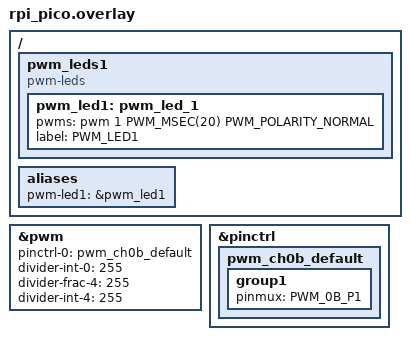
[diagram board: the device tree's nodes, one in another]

#include </home/tatiana/zephyrproject/zephyr/include/zephyr/dt-bindings/pinctrl/rpi-pico-rp2040-pinctrl.h>

/ {
	pwm_leds1 {
		compatible = "pwm-leds";
		pwm_led1: pwm_led_1 {
			status = "okay";
			pwms = <&pwm 1 PWM_MSEC(20) PWM_POLARITY_NORMAL>;
			label = "PWM_LED1";
		};
	};

	aliases {
		pwm-led1 = &pwm_led1;
	};
};


&pwm {
	pinctrl-0 = <&pwm_ch0b_default>;
	pinctrl-names = "default";
	divider-int-0 = <255>;
	status = "okay";
	divider-frac-4 = <255>;
	divider-int-4 = <255>;
};
&pinctrl {
	pwm_ch0b_default: pwm_ch0b_default {
		group1 {
			pinmux = <PWM_0B_P1>;
		};
	};
};
